AUTOSAR XML (schema 4-3-0)
package /cdd_slpwup
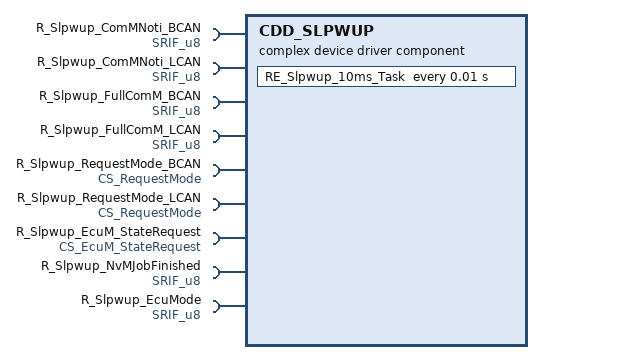
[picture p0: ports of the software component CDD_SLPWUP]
  complex device driver sw component type CDD_SLPWUP
    9 x require port:
      R_Slpwup_ComMNoti_BCAN: nonqueued-receiver-com-spec=SR_u8, required-interface=SRIF_u8
      R_Slpwup_ComMNoti_LCAN: nonqueued-receiver-com-spec=SR_u8, required-interface=SRIF_u8
      R_Slpwup_FullComM_BCAN: nonqueued-receiver-com-spec=SR_u8, required-interface=SRIF_u8
      R_Slpwup_FullComM_LCAN: nonqueued-receiver-com-spec=SR_u8, required-interface=SRIF_u8
      R_Slpwup_RequestMode_BCAN: required-interface=CS_RequestMode
      R_Slpwup_RequestMode_LCAN: required-interface=CS_RequestMode
      R_Slpwup_EcuM_StateRequest: required-interface=CS_EcuM_StateRequest
      R_Slpwup_NvMJobFinished: nonqueued-receiver-com-spec=SR_u8, required-interface=SRIF_u8
      R_Slpwup_EcuMode: nonqueued-receiver-com-spec=SR_u8, required-interface=SRIF_u8
    behavior InternalBehavior
      timing event TE_RE_Slpwup_10ms_Task: start-on-event=RE_Slpwup_10ms_Task, period=0.01
      runnable RE_Slpwup_10ms_Task: symbol=Slpwup_10ms_Task
        data-receive-point-by-arguments:
          6 x access, all with scope=COMMUNICATION-INTER-ECU:
            DRPBA_RE_Slpwup_10ms_Task_R_Slpwup_ComMNoti_BCAN_SR_u8: accessed-variable=R_Slpwup_ComMNoti_BCAN.SR_u8
            DRPBA_RE_Slpwup_10ms_Task_R_Slpwup_ComMNoti_LCAN_SR_u8: accessed-variable=R_Slpwup_ComMNoti_LCAN.SR_u8
            DRPBA_RE_Slpwup_10ms_Task_R_Slpwup_FullComM_BCAN_SR_u8: accessed-variable=R_Slpwup_FullComM_BCAN.SR_u8
            DRPBA_RE_Slpwup_10ms_Task_R_Slpwup_FullComM_LCAN_SR_u8: accessed-variable=R_Slpwup_FullComM_LCAN.SR_u8
            DRPBA_RE_Slpwup_10ms_Task_R_Slpwup_NvMJobFinished_SR_u8: accessed-variable=R_Slpwup_NvMJobFinished.SR_u8
            DRPBA_RE_Slpwup_10ms_Task_R_Slpwup_EcuMode_SR_u8: accessed-variable=R_Slpwup_EcuMode.SR_u8
        sync call SSCP_RE_Slpwup_10ms_Task_R_RequestMode_BCAN_RequestComMode: operation=R_Slpwup_RequestMode_BCAN.RequestComMode
        sync call SSCP_RE_Slpwup_10ms_Task_R_RequestMode_LCAN_RequestComMode: operation=R_Slpwup_RequestMode_LCAN.RequestComMode
        sync call SSCP_RE_Slpwup_10ms_Task_R_Slpwup_EcuM_StateRequest_RequestState: operation=R_Slpwup_EcuM_StateRequest.RequestState
